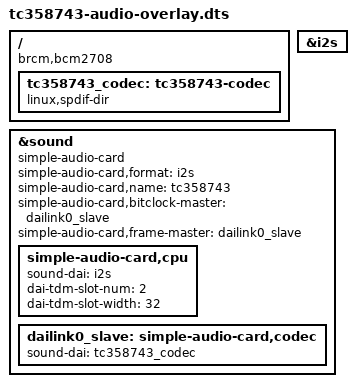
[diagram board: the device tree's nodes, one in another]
// SPDX-License-Identifier: GPL-2.0-only
// Definitions to add I2S audio from the Toshiba TC358743 HDMI to CSI2 bridge.
// Requires tc358743 overlay to have been loaded to actually function.
/dts-v1/;
/plugin/;

/ {
	compatible = "brcm,bcm2708";

	fragment@0 {
		target = <&i2s>;
		__overlay__ {
			status = "okay";
		};
	};

	fragment@1 {
		target-path = "/";
		__overlay__ {
			tc358743_codec: tc358743-codec {
				#sound-dai-cells = <0>;
				compatible = "linux,spdif-dir";
				status = "okay";
			};
		};
	};

	fragment@2 {
		target = <&sound>;
		sound_overlay: __overlay__ {
			compatible = "simple-audio-card";
			simple-audio-card,format = "i2s";
			simple-audio-card,name = "tc358743";
			simple-audio-card,bitclock-master = <&dailink0_slave>;
			simple-audio-card,frame-master = <&dailink0_slave>;
			status = "okay";

			simple-audio-card,cpu {
				sound-dai = <&i2s>;
				dai-tdm-slot-num = <2>;
				dai-tdm-slot-width = <32>;
			};
			dailink0_slave: simple-audio-card,codec {
				sound-dai = <&tc358743_codec>;
			};
		};
	};

	__overrides__ {
		card-name = <&sound_overlay>,"simple-audio-card,name";
	};
};
